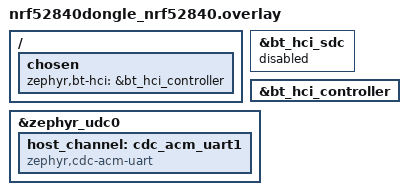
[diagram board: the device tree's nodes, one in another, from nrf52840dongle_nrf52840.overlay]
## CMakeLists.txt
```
cmake_minimum_required(VERSION 3.20.0)

find_package(Zephyr REQUIRED HINTS $ENV{ZEPHYR_BASE})
project(nordicpad_dongle)

set(BTSTACK_ROOT "$ENV{HOME}/code/pico-sdk/lib/btstack" CACHE PATH "BTstack source tree")
set(NORDICPAD_DIR ${CMAKE_CURRENT_LIST_DIR}/..)
set(SOURCE_DIR ${NORDICPAD_DIR}/src)
set(GENERATED_IDENTITY ${SOURCE_DIR}/generated/identity_data.c)
set(GATT_FILE ${SOURCE_DIR}/ble/pro/nordicpad.gatt)
set(GATT_OUTPUT_DIR ${CMAKE_CURRENT_BINARY_DIR}/generated)

if(NOT EXISTS ${GENERATED_IDENTITY})
    message(FATAL_ERROR "Missing ${GENERATED_IDENTITY}: run scripts/extract_fixtures.exs on a capture first")
endif()

find_package(Python3 REQUIRED COMPONENTS Interpreter)

file(MAKE_DIRECTORY ${GATT_OUTPUT_DIR})
add_custom_command(
    OUTPUT ${GATT_OUTPUT_DIR}/nordicpad.h
    DEPENDS ${GATT_FILE}
    COMMAND ${Python3_EXECUTABLE} ${BTSTACK_ROOT}/tool/compile_gatt.py ${GATT_FILE} ${GATT_OUTPUT_DIR}/nordicpad.h
)
add_custom_target(nordicpad_gatt_header DEPENDS ${GATT_OUTPUT_DIR}/nordicpad.h)

file(GLOB BTSTACK_CORE ${BTSTACK_ROOT}/src/*.c)
file(GLOB BTSTACK_BLE ${BTSTACK_ROOT}/src/ble/*.c)
file(GLOB BTSTACK_ZEPHYR ${BTSTACK_ROOT}/chipset/zephyr/*.c)
list(FILTER BTSTACK_CORE EXCLUDE REGEX "lc3|hci_transport_")
list(REMOVE_ITEM BTSTACK_BLE ${BTSTACK_ROOT}/src/ble/le_device_db_tlv.c)

include(${NORDICPAD_DIR}/cmake/nordicpad_core_sources.cmake)
list(FILTER NORDICPAD_CORE_SOURCES EXCLUDE REGEX "file_pairing_store")

add_dependencies(app nordicpad_gatt_header)

target_sources(app PRIVATE
    ${GENERATED_IDENTITY}
    ${BTSTACK_CORE}
    ${BTSTACK_BLE}
    ${BTSTACK_ZEPHYR}
    ${BTSTACK_ROOT}/3rd-party/rijndael/rijndael.c
    ${NORDICPAD_CORE_SOURCES}
    ${BTSTACK_ROOT}/platform/embedded/hci_dump_embedded_stdout.c
    ${CMAKE_CURRENT_LIST_DIR}/src/main.c
    ${CMAKE_CURRENT_LIST_DIR}/src/reboot.c
    ${SOURCE_DIR}/app/app.c
    ${SOURCE_DIR}/app/host_service.c
    ${SOURCE_DIR}/ble/ble_diagnostics.c
    ${SOURCE_DIR}/ble/ble_link_key.c
    ${SOURCE_DIR}/ble/ble_peripheral.c
    ${SOURCE_DIR}/ble/gatt_bridge.c
    ${SOURCE_DIR}/platform/mac_ble_platform.c
    ${SOURCE_DIR}/platform/zephyr_cdc_transport.c
    ${SOURCE_DIR}/platform/zephyr_chipset.c
    ${SOURCE_DIR}/platform/zephyr_hci_transport.c
    ${SOURCE_DIR}/platform/zephyr_run_loop.c
    ${SOURCE_DIR}/storage/zephyr_flash_pairing_store.c
)

target_include_directories(app PRIVATE
    ${CMAKE_CURRENT_LIST_DIR}
    ${GATT_OUTPUT_DIR}
    ${SOURCE_DIR}
    ${BTSTACK_ROOT}/src
    ${BTSTACK_ROOT}/chipset/zephyr
    ${BTSTACK_ROOT}/platform/embedded
    ${BTSTACK_ROOT}/3rd-party/rijndael
)

target_compile_definitions(app PRIVATE NORDICPAD_PRO_CONTROLLER)

option(NORDICPAD_DONGLE_HCI_DUMP "Print every HCI packet on the console port" OFF)
if(NORDICPAD_DONGLE_HCI_DUMP)
    target_compile_definitions(app PRIVATE NORDICPAD_DONGLE_HCI_DUMP)
endif()
```

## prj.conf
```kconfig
CONFIG_BT=y
CONFIG_REBOOT=y
CONFIG_BT_HCI_RAW=y
CONFIG_BT_HCI_VS=y
CONFIG_BT_LL_SW_SPLIT=y
CONFIG_BT_CTLR_ASSERT_HANDLER=y
CONFIG_BT_CTLR_DATA_LENGTH_MAX=251
CONFIG_BT_BUF_ACL_TX_SIZE=251
CONFIG_BT_BUF_ACL_RX_SIZE=255
CONFIG_BT_BUF_CMD_TX_SIZE=255
CONFIG_BT_BUF_EVT_DISCARDABLE_SIZE=255
CONFIG_BT_BUF_CMD_TX_COUNT=10
CONFIG_BT_MAX_CONN=1
CONFIG_BT_TINYCRYPT_ECC=n
CONFIG_SYSTEM_WORKQUEUE_STACK_SIZE=1024
CONFIG_MAIN_STACK_SIZE=8192
CONFIG_FLASH=y
CONFIG_FLASH_MAP=y
CONFIG_CONSOLE=y
CONFIG_UART_CONSOLE=y
CONFIG_USB_DEVICE_STACK=y
CONFIG_USB_CDC_ACM=y
CONFIG_USB_DEVICE_INITIALIZE_AT_BOOT=n
CONFIG_USB_DEVICE_PRODUCT="nordicpad dongle"
CONFIG_NEWLIB_LIBC=y
```

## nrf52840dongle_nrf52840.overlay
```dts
/ {
	chosen {
		zephyr,bt-hci = &bt_hci_controller;
	};
};

&bt_hci_sdc {
	status = "disabled";
};

&bt_hci_controller {
	status = "okay";
};

&zephyr_udc0 {
	host_channel: cdc_acm_uart1 {
		compatible = "zephyr,cdc-acm-uart";
	};
};
```

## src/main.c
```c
#include <zephyr/kernel.h>
#include <zephyr/usb/usb_device.h>

#include "app/app.h"
#include "btstack.h"
#include "btstack_memory.h"
#include "platform/mac_ble_platform.h"
#include "platform/zephyr_cdc_transport.h"
#include "platform/zephyr_chipset.h"
#include "platform/zephyr_hci_transport.h"
#include "platform/zephyr_run_loop.h"
#include "reboot.h"
#include "storage/zephyr_flash_pairing_store.h"

#ifdef NORDICPAD_DONGLE_HCI_DUMP
#include "hci_dump_embedded_stdout.h"
#endif

#define CONSOLE_ATTACH_DELAY_MS 4000

void bt_ctlr_assert_handle(char *file, uint32_t line) {
    printk("controller assert: %s:%u\n", file, line);
    while (true) {
    }
}

int main(void) {
    usb_enable(NULL);
    k_msleep(CONSOLE_ATTACH_DELAY_MS);

    btstack_memory_init();
    btstack_run_loop_init(zephyr_run_loop_instance());
#ifdef NORDICPAD_DONGLE_HCI_DUMP
    hci_dump_init(hci_dump_embedded_stdout_get_instance());
#endif
    hci_init(zephyr_hci_transport_instance(), NULL);
    hci_set_chipset(zephyr_chipset_with_public_address());

    static zephyr_cdc_transport_t host_channel;
    zephyr_cdc_transport_init(&host_channel, DEVICE_DT_GET(DT_NODELABEL(host_channel)));

    const app_platform_t platform = {
        .pairing_store = zephyr_flash_pairing_store(),
        .ble = MAC_BLE_PLATFORM,
        .host = zephyr_cdc_transport_interface(&host_channel),
        .system = {dongle_reboot, NULL},
    };
    return app_run(&platform);
}
```

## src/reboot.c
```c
#include "reboot.h"

#include <zephyr/devicetree.h>
#include <zephyr/drivers/flash.h>
#include <zephyr/kernel.h>
#include <zephyr/linker/linker-defs.h>
#include <zephyr/sys/reboot.h>

#include "platform/log.h"

#define REBOOT_DELAY_MS 300
#define ERASE_SIZE 4096

static host_reboot_target_t pending_target;

static const struct device *flash_device(void) {
    return DEVICE_DT_GET(DT_CHOSEN(zephyr_flash_controller));
}

static void invalidate_application(void) {
    uintptr_t last_byte = (uintptr_t)__rom_region_start + (uintptr_t)_flash_used - 1;
    off_t page = (off_t)(last_byte & ~((uintptr_t)ERASE_SIZE - 1));

    int result = flash_erase(flash_device(), page, ERASE_SIZE);
    LOG("erased image page 0x%lx for the bootloader: %d", (unsigned long)page, result);
}

static void perform_reboot(struct k_work *work) {
    (void)work;
    if (pending_target == HOST_REBOOT_BOOTLOADER) {
        invalidate_application();
    }
    sys_reboot(SYS_REBOOT_COLD);
}

static K_WORK_DELAYABLE_DEFINE(reboot_work, perform_reboot);

void dongle_reboot(void *context, host_reboot_target_t target) {
    (void)context;
    pending_target = target;
    k_work_schedule(&reboot_work, K_MSEC(REBOOT_DELAY_MS));
}
```

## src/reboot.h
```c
#ifndef DONGLE_REBOOT_H
#define DONGLE_REBOOT_H

#include "host/host_ids.h"

void dongle_reboot(void *context, host_reboot_target_t target);

#endif
```
